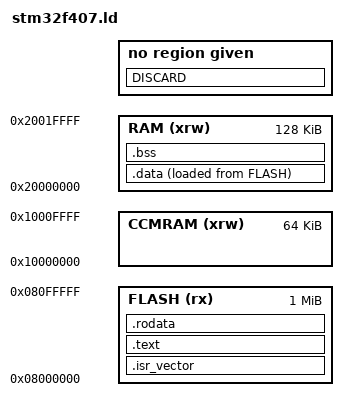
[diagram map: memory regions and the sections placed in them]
/*
 * Copyright (c) 2015 Ambroz Bizjak
 * All rights reserved.
 * 
 * Redistribution and use in source and binary forms, with or without
 * modification, are permitted provided that the following conditions are met:
 * 1. Redistributions of source code must retain the above copyright
 *    notice, this list of conditions and the following disclaimer.
 * 2. Redistributions in binary form must reproduce the above copyright
 *    notice, this list of conditions and the following disclaimer in the
 *    documentation and/or other materials provided with the distribution.
 * 
 * THIS SOFTWARE IS PROVIDED BY THE COPYRIGHT HOLDERS AND CONTRIBUTORS "AS IS" AND
 * ANY EXPRESS OR IMPLIED WARRANTIES, INCLUDING, BUT NOT LIMITED TO, THE IMPLIED
 * WARRANTIES OF MERCHANTABILITY AND FITNESS FOR A PARTICULAR PURPOSE ARE
 * DISCLAIMED. IN NO EVENT SHALL THE AUTHOR BE LIABLE FOR ANY
 * DIRECT, INDIRECT, INCIDENTAL, SPECIAL, EXEMPLARY, OR CONSEQUENTIAL DAMAGES
 * (INCLUDING, BUT NOT LIMITED TO, PROCUREMENT OF SUBSTITUTE GOODS OR SERVICES;
 * LOSS OF USE, DATA, OR PROFITS; OR BUSINESS INTERRUPTION) HOWEVER CAUSED AND
 * ON ANY THEORY OF LIABILITY, WHETHER IN CONTRACT, STRICT LIABILITY, OR TORT
 * (INCLUDING NEGLIGENCE OR OTHERWISE) ARISING IN ANY WAY OUT OF THE USE OF THIS
 * SOFTWARE, EVEN IF ADVISED OF THE POSSIBILITY OF SUCH DAMAGE.
 */

MEMORY
{
    RAM (xrw) :    ORIGIN = 0x20000000, LENGTH = 128K
    CCMRAM (xrw) : ORIGIN = 0x10000000, LENGTH = 64K
    FLASH (rx) :   ORIGIN = 0x8000000,  LENGTH = 1024K
}

/* End of stack is at end of RAM. And NOT one less. See:
   http://stackoverflow.com/a/28761856/1020667 */
_estack = ORIGIN(RAM) + LENGTH(RAM);

SECTIONS
{
    .isr_vector :
    {
        . = ALIGN(4);
        KEEP(*(.isr_vector))
        . = ALIGN(4);
    } >FLASH
    
    .text :
    {
        . = ALIGN(4);
        *(.text)
        *(.text.*)
        *(.glue_7)
        *(.glue_7t)
        KEEP(*(.init))
        KEEP(*(.fini))
        . = ALIGN(4);
        _etext = .;
    } >FLASH
    
    .rodata :
    {
        . = ALIGN(4);
        *(.rodata)
        *(.rodata.*)
        . = ALIGN(4);
        PROVIDE_HIDDEN (__preinit_array_start = .);
        KEEP(*(.preinit_array*))
        PROVIDE_HIDDEN (__preinit_array_end = .);
        . = ALIGN(4);
        PROVIDE_HIDDEN (__init_array_start = .);
        KEEP(*(SORT(.init_array.*)))
        KEEP(*(.init_array))
        PROVIDE_HIDDEN (__init_array_end = .);
        . = ALIGN(4);
        PROVIDE_HIDDEN (__fini_array_start = .);
        KEEP(*(.fini_array))
        KEEP(*(SORT(.fini_array.*)))
        PROVIDE_HIDDEN (__fini_array_end = .);
        . = ALIGN(4);
    } >FLASH
    
    _sidata = LOADADDR(.data);
    
    .data :
    {
        . = ALIGN(4);
        _sdata = .;
        *(.data)
        *(.data.*)
        . = ALIGN(4);
        _edata = .;
    } >RAM AT> FLASH
    
    .bss :
    {
        . = ALIGN(4);
        _sbss = .;
        *(.bss)
        *(.bss.*)
        *(COMMON)
        . = ALIGN(4);
        _ebss = .;
    } >RAM
    
    PROVIDE ( _end = _ebss );
    
    DISCARD :
    {
        libgcc.a ( * )
        libc.a ( * )
        libm.a ( * )
    }
}
